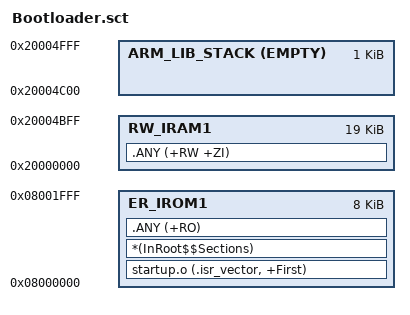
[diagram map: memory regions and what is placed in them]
; BOOTLOADER: Flash 0x08000000, 8 KiB, RAM 20 KiB. Khớp common/ota_frame/ota_layout.h.
; ARM Compiler 6 full C runtime (__main). Do not enable MicroLIB.
LR_IROM1 0x08000000 0x00002000 {
  ER_IROM1 0x08000000 0x00002000 {
    startup.o (.isr_vector, +First)
    *(InRoot$$Sections)
    .ANY (+RO)
  }
  RW_IRAM1 0x20000000 0x00004C00 { .ANY (+RW +ZI) }
  ARM_LIB_STACK 0x20005000 EMPTY -0x00000400 { }
}
